AUTOSAR XML (schema 4-2-1)
package /ComponentTypes
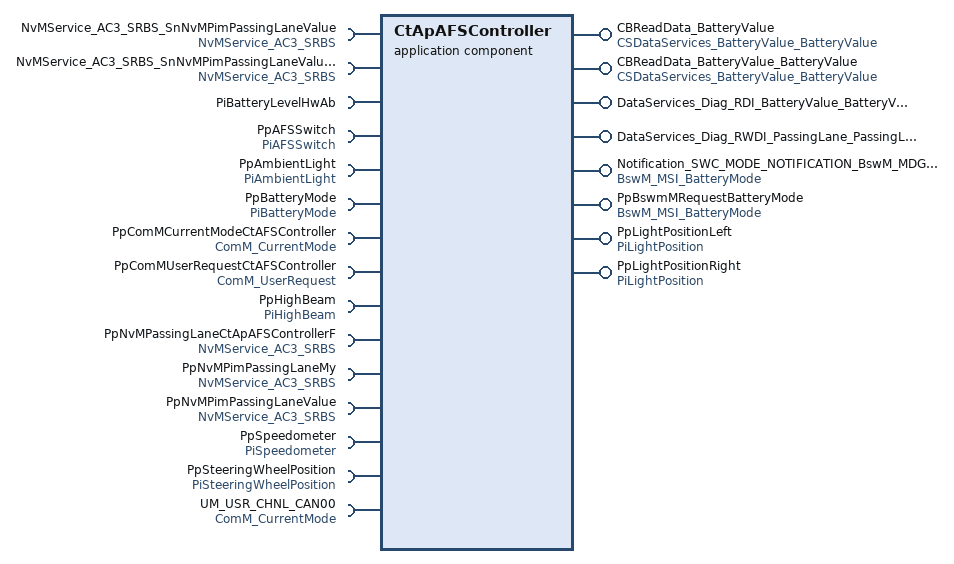
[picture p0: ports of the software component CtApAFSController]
  application sw component type CtApAFSController
    8 x provide port:
      CBReadData_BatteryValue: server-com-spec{operation=ReadData, queue-length=1}, provided-interface=CSDataServices_BatteryValue_BatteryValue
      CBReadData_BatteryValue_BatteryValue: server-com-spec{operation=ReadData, queue-length=1}, provided-interface=CSDataServices_BatteryValue_BatteryValue
      DataServices_Diag_RDI_BatteryValue_BatteryValue: provided-com-specs=[{operation=ConditionCheckRead, queue-length=1}, {operation=ReadData, queue-length=1}], provided-interface=DataServices_Diag_RDI_BatteryValue_BatteryValue
      DataServices_Diag_RWDI_PassingLane_PassingLane_PassingLane: provided-interface=DataServices_Diag_RWDI_PassingLane_PassingLane_PassingLane
        provided-com-specs:
          operation=ConditionCheckRead, queue-length=1
          operation=ReadData, queue-length=1
          operation=WriteData, queue-length=1
      Notification_SWC_MODE_NOTIFICATION_BswM_MDGP_BatteryMode: mode-switch-sender-com-spec{enhanced-mode-api=false, mode-group=BswM_MDGP_BatteryMode, queue-length=1}, provided-interface=BswM_MSI_BatteryMode
      PpBswmMRequestBatteryMode: mode-switch-sender-com-spec{enhanced-mode-api=false, mode-group=BswM_MDGP_BatteryMode, queue-length=1}, provided-interface=BswM_MSI_BatteryMode
      PpLightPositionLeft: provided-com-specs=[{data-element=DeLightLength, init-value=0}, {data-element=DeLightPosition, init-value=0}], provided-interface=PiLightPosition
      PpLightPositionRight: provided-interface=PiLightPosition
        provided-com-specs:
          data-element=DeLightLength, init-value=0
          data-element=DeLightPosition, init-value=constant-reference=CDarkLight
    15 x require port:
      NvMService_AC3_SRBS_SnNvMPimPassingLaneValue: required-interface=NvMService_AC3_SRBS
      NvMService_AC3_SRBS_SnNvMPimPassingLaneValue_1: required-interface=NvMService_AC3_SRBS
      PiBatteryLevelHwAb: required-interface=PiBatteryLevelHwAb
      PpAFSSwitch: required-interface=PiAFSSwitch
      PpAmbientLight: nonqueued-receiver-com-spec{data-element=DeAmbientLight, filter=data-filter-type=ALWAYS, init-value=constant-reference=CDarkLight}, required-interface=PiAmbientLight
      PpBatteryMode: mode-switch-receiver-com-spec{enhanced-mode-api=false, supports-asynchronous-mode-switch=false}, required-interface=PiBatteryMode
      PpComMCurrentModeCtAFSController: mode-switch-receiver-com-spec{enhanced-mode-api=false, supports-asynchronous-mode-switch=false}, required-interface=ComM_CurrentMode
      PpComMUserRequestCtAFSController: required-interface=ComM_UserRequest
      PpHighBeam: required-interface=PiHighBeam
      PpNvMPassingLaneCtApAFSControllerF: required-interface=NvMService_AC3_SRBS
      PpNvMPimPassingLaneMy: required-interface=NvMService_AC3_SRBS
      PpNvMPimPassingLaneValue: required-interface=NvMService_AC3_SRBS
      PpSpeedometer: nonqueued-receiver-com-spec{data-element=DeSpeedometer, filter=data-filter-type=ALWAYS, init-value=constant-reference=CInitSpeed}, required-interface=PiSpeedometer
      PpSteeringWheelPosition: nonqueued-receiver-com-spec{data-element=DeSteeringWheelPosition, filter=data-filter-type=ALWAYS, init-value=0}, required-interface=PiSteeringWheelPosition
      UM_USR_CHNL_CAN00: mode-switch-receiver-com-spec{enhanced-mode-api=false, supports-asynchronous-mode-switch=false}, required-interface=ComM_CurrentMode
    behavior CtApAFSController_InternalBehavior
      exclusive area ExArBatteryValue
      exclusive area ExArPassLaneValue
      ar-typed-per-instance-memorys:
        data PimPassingLane: sw-calibration-access=READ-ONLY, type=IdtPassingLane
      6 x operation invoked event:
        OIT_CBReadData_BatteryValue_ReadData_CBReadData_BatteryValue_ReadData: start-on-event=CBReadData_BatteryValue_ReadData, operation=CBReadData_BatteryValue.ReadData
        OIT_DataServices_Diag_RDI_BatteryValue_BatteryValue_ConditionCheckRead_DataServices_Diag_RDI_BatteryValue_BatteryValue_C3B28864A: start-on-event=DataServices_Diag_RDI_BatteryValue_BatteryValue_ConditionCheckRead, operation=DataServices_Diag_RDI_BatteryValue_BatteryValue.ConditionCheckRead
        OIT_DataServices_Diag_RDI_BatteryValue_BatteryValue_ReadData_DataServices_Diag_RDI_BatteryValue_BatteryValue_ReadData: start-on-event=DataServices_Diag_RDI_BatteryValue_BatteryValue_ReadData, operation=DataServices_Diag_RDI_BatteryValue_BatteryValue.ReadData
        OIT_DataServices_Diag_RWDI_PassingLane_PassingLane_PassingLane_ConditionCheckRead_DataServices_Diag_RWDI_PassingLane_Pas5F15AC2B: start-on-event=DataServices_Diag_RWDI_PassingLane_PassingLane_PassingLane_ConditionCheckRead, operation=DataServices_Diag_RWDI_PassingLane_PassingLane_PassingLane.ConditionCheckRead
        OIT_DataServices_Diag_RWDI_PassingLane_PassingLane_PassingLane_ReadData_DataServices_Diag_RWDI_PassingLane_PassingLane_P8D71540F: start-on-event=DataServices_Diag_RWDI_PassingLane_PassingLane_PassingLane_ReadData, operation=DataServices_Diag_RWDI_PassingLane_PassingLane_PassingLane.ReadData
        OIT_DataServices_Diag_RWDI_PassingLane_PassingLane_PassingLane_WriteData_DataServices_Diag_RWDI_PassingLane_PassingLane_DA0BE9C4: start-on-event=DataServices_Diag_RWDI_PassingLane_PassingLane_PassingLane_WriteData, operation=DataServices_Diag_RWDI_PassingLane_PassingLane_PassingLane.WriteData
      init event CtApAFSController_InitEvent: start-on-event=RCtApAFSController_Init
      swc mode switch event MST_RCtApAFSControllerComM_ModeChange_FULL_COMM_Entry_0: start-on-event=RCtApAFSController_ModeChange_HighBeam, activation=ON-ENTRY, mode=PpBatteryMode.BatteryMode.BATTERY_LOW
      data received event DRT_RCtApAFSControllerLogic_PpSteeringWheelPosition_DeSteeringWheelPosition: disabled-mode=PpBatteryMode.BatteryMode.BATTERY_LOW, start-on-event=RCtApAFSControllerLogic, data=PpSteeringWheelPosition.DeSteeringWheelPosition
      9 x runnable:
        CBReadData_BatteryValue_ReadData: can-enter-exclusive-area=ExArBatteryValue
          sync call SC_PiBatteryLevelHwAb_ReadChannel: operation=PiBatteryLevelHwAb.ReadChannel, timeout=0
        DataServices_Diag_RDI_BatteryValue_BatteryValue_ConditionCheckRead
        DataServices_Diag_RDI_BatteryValue_BatteryValue_ReadData: can-enter-exclusive-area=ExArBatteryValue
        DataServices_Diag_RWDI_PassingLane_PassingLane_PassingLane_ConditionCheckRead: can-enter-exclusive-area=ExArPassLaneValue
        DataServices_Diag_RWDI_PassingLane_PassingLane_PassingLane_ReadData: can-enter-exclusive-area=ExArPassLaneValue
          sync call SC_PpNvMPassingLaneCtApAFSControllerF_ReadBlock: operation=PpNvMPassingLaneCtApAFSControllerF.ReadBlock, timeout=0
        DataServices_Diag_RWDI_PassingLane_PassingLane_PassingLane_WriteData: can-enter-exclusive-area=ExArPassLaneValue
          sync call SC_PpNvMPassingLaneCtApAFSControllerF_WriteBlock: operation=PpNvMPassingLaneCtApAFSControllerF.WriteBlock, timeout=0
        RCtApAFSController_Init: can-enter-exclusive-area=[ExArBatteryValue, ExArPassLaneValue]
          sync call SC_PpNvMPassingLaneCtApAFSControllerF_ReadBlock: operation=PpNvMPassingLaneCtApAFSControllerF.ReadBlock, timeout=0
        RCtApAFSController_ModeChange_HighBeam
          data-send-points:
            4 x access:
              SEND_PpLightPositionLeft_DeLightLength: accessed-variable=PpLightPositionLeft.DeLightLength
              SEND_PpLightPositionLeft_DeLightPosition: accessed-variable=PpLightPositionLeft.DeLightPosition
              SEND_PpLightPositionRight_DeLightLength: accessed-variable=PpLightPositionRight.DeLightLength
              SEND_PpLightPositionRight_DeLightPosition: accessed-variable=PpLightPositionRight.DeLightPosition
        RCtApAFSControllerLogic: can-enter-exclusive-area=[ExArBatteryValue, ExArPassLaneValue], mode-access-point=PpBatteryMode.BatteryMode
          data-receive-point-by-arguments:
            access REC_PpAmbientLight_DeAmbientLight: accessed-variable=PpAmbientLight.DeAmbientLight
            access REC_PpSpeedometer_DeSpeedometer: accessed-variable=PpSpeedometer.DeSpeedometer
            access REC_PpSteeringWheelPosition_DeSteeringWheelPosition: accessed-variable=PpSteeringWheelPosition.DeSteeringWheelPosition
          data-send-points:
            4 x access:
              SEND_PpLightPosition_DeLightPosition: accessed-variable=PpLightPositionLeft.DeLightPosition
              SEND_PpLightPositionLeft_DeLightMode: accessed-variable=PpLightPositionLeft.DeLightLength
              SEND_PpLightPositionRight_DeLightMode: accessed-variable=PpLightPositionRight.DeLightLength
              SEND_PpLightPositionRight_DeLightPosition: accessed-variable=PpLightPositionRight.DeLightPosition
          4 x sync call, all with timeout=0:
            SC_PpAFSSwitch_ReadChannel: operation=PpAFSSwitch.ReadChannel
            SC_PpComMUserRequestCtAFSController_RequestComMode: operation=PpComMUserRequestCtAFSController.RequestComMode
            SC_PpHighBeam_ReadChannel: operation=PpHighBeam.ReadChannel
            SC_PpNvMPassingLaneCtApAFSControllerF_ReadBlock: operation=PpNvMPassingLaneCtApAFSControllerF.ReadBlock
      swc service dependency SnNvMPimPassingLaneF: assigned-datas=role-based-data-assignment={role=ramBlock, used-data-element=PimPassingLane}
        assigned-ports:
          port-prototype=PpNvMPassingLaneCtApAFSControllerF, role=NvMService_AC3_SRBS
          port-prototype=PpNvMPassingLaneCtApAFSControllerF, role=NvMService_AC3_SRBS
        service-needs:
          nv block needs SnNvMPimPassingLaneF: readonly=false, resistant-to-changed-sw=false, restore-at-start=true, store-at-shutdown=true, write-only-once=false
  swc implementation CtApAFSController_Implementation: behavior=CtApAFSController_InternalBehavior
    code-descriptors:
      code Default: artifact-descriptors=autosar-engineering-object={short-label=Default, category=SWSRC}
